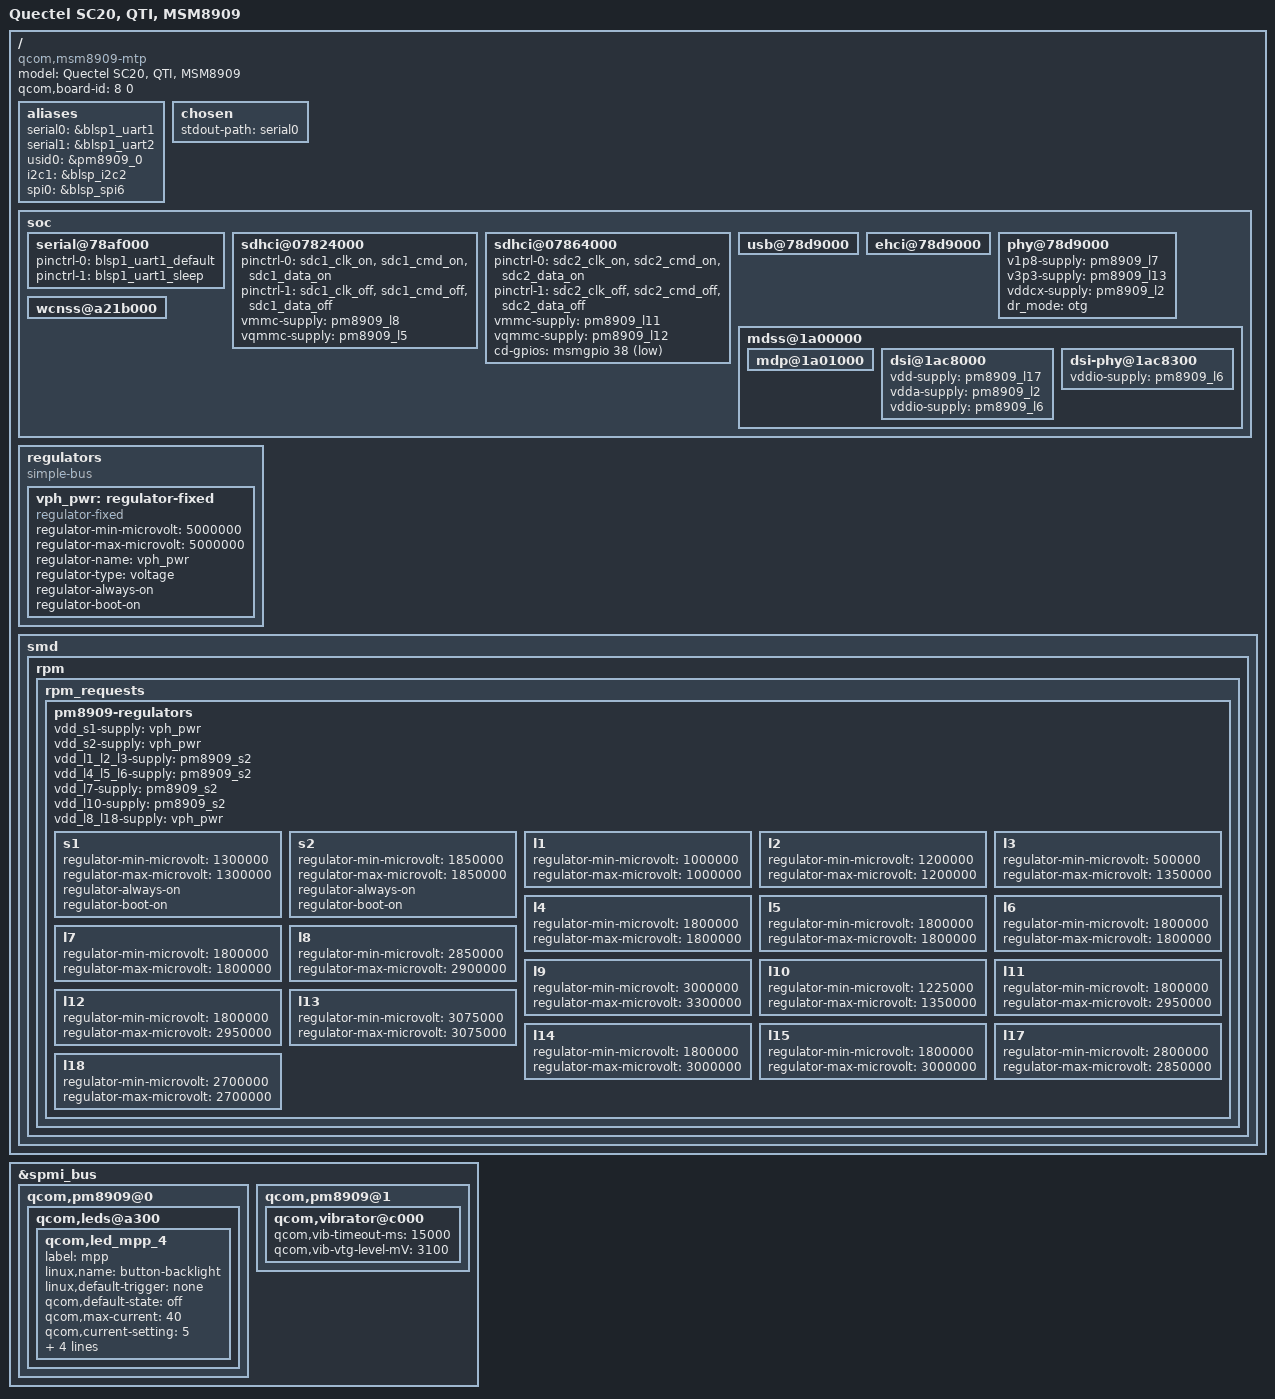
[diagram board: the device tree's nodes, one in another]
// SPDX-License-Identifier: GPL-2.0
/* Copyright (c) 2016, The Linux Foundation. All rights reserved. */
/* Copyright (c) 2019, Ramon Rebersak <ramonr@aplit-soft.com> */
/dts-v1/;

#include "qcom-msm8909.dtsi"
#include "qcom-pm8909.dtsi"
#include <dt-bindings/gpio/gpio.h>
#include <dt-bindings/input/input.h>

/ {
	model = "Quectel SC20, QTI, MSM8909";
	compatible = "qcom,msm8909-mtp", "qcom,msm8909", "qcom,mtp";
	qcom,board-id = <8 0>;

	aliases {
		serial0 = &blsp1_uart1;
		serial1 = &blsp1_uart2;
		usid0 = &pm8909_0;
		i2c1	= &blsp_i2c2;
		spi0	= &blsp_spi6;

	};

	chosen {
		stdout-path = "serial0";
	};

	soc {
		serial@78af000 {
			status = "okay";
			pinctrl-names = "default", "sleep";
			pinctrl-0 = <&blsp1_uart1_default>;
			pinctrl-1 = <&blsp1_uart1_sleep>;
		};
//
//		sdhci@7824000 {
//			vmmc-supply = <&pm8909_l8>;
//			vqmmc-supply = <&pm8909_l5>;
//
//			pinctrl-names = "default", "sleep";
//			pinctrl-0 = <&sdc1_clk_on &sdc1_cmd_on &sdc1_data_on>;
//			pinctrl-1 = <&sdc1_clk_off &sdc1_cmd_off &sdc1_data_off>;
//			status = "okay";
//		};
//
//		sdhci@07864000 {
//			vmmc-supply = <&pm8909_l11>;
//			vqmmc-supply = <&pm8909_l12>;
//
//			pinctrl-names = "default", "sleep";
//			pinctrl-0 = <&sdc2_clk_on &sdc2_cmd_on &sdc2_data_on &sdc2_cd_on>;
//			pinctrl-1 = <&sdc2_clk_off &sdc2_cmd_off &sdc2_data_off &sdc2_cd_off>;
//
//			cd-gpios = <&msmgpio 38 0x1>;
//			status = "okay";
//		};
///
		sdhci@07824000 {
			status = "okay";
			pinctrl-names = "default", "sleep";
			pinctrl-0 = <&sdc1_clk_on &sdc1_cmd_on &sdc1_data_on>;
			pinctrl-1 = <&sdc1_clk_off &sdc1_cmd_off &sdc1_data_off>;
			vmmc-supply = <&pm8909_l8>;
			vqmmc-supply = <&pm8909_l5>;
		};

		sdhci@07864000 {
			status = "okay";
			pinctrl-names = "default", "sleep";
			pinctrl-0 = <&sdc2_clk_on &sdc2_cmd_on &sdc2_data_on>;
			pinctrl-1 = <&sdc2_clk_off &sdc2_cmd_off &sdc2_data_off>;
			vmmc-supply = <&pm8909_l11>;
			vqmmc-supply = <&pm8909_l12>;
			cd-gpios = <&msmgpio 38 0x1>;
		};

		usb@78d9000 {
			status = "okay";
		};

		ehci@78d9000 {
			status = "okay";
		};

		phy@78d9000 {
			v1p8-supply = <&pm8909_l7>;
			v3p3-supply = <&pm8909_l13>;
			vddcx-supply = <&pm8909_l2>;
			dr_mode = "otg";
			status = "okay";
		};

		mdss@1a00000 {
			status = "okay";

			mdp@1a01000 {
				status = "okay";
			};

			dsi@1ac8000 {
				status = "okay";

				vdd-supply = <&pm8909_l17>;
				vdda-supply = <&pm8909_l2>;
				vddio-supply = <&pm8909_l6>;
			};

			dsi-phy@1ac8300 {
				status = "okay";

				vddio-supply = <&pm8909_l6>;
			};
		};

		wcnss@a21b000 {
			status = "okay";
                };
	};

	regulators {
		compatible = "simple-bus";

		vph_pwr: regulator-fixed {
			compatible = "regulator-fixed";
			regulator-min-microvolt = <5000000>;
			regulator-max-microvolt = <5000000>;
			regulator-name = "vph_pwr";
			regulator-type = "voltage";
			regulator-always-on;
			regulator-boot-on;
		};

	};

	smd {
		rpm {
			rpm_requests {
				pm8909-regulators {
					vdd_s1-supply = <&vph_pwr>;
					vdd_s2-supply = <&vph_pwr>;
					vdd_l1_l2_l3-supply = <&pm8909_s2>;
					vdd_l4_l5_l6-supply = <&pm8909_s2>;
					vdd_l7-supply = <&pm8909_s2>;
					vdd_l10-supply = <&pm8909_s2>;
					vdd_l8_l18-supply = <&vph_pwr>;

					s1 {
						regulator-min-microvolt = <1300000>;
						regulator-max-microvolt = <1300000>;
						regulator-always-on;
						regulator-boot-on;
					};

					s2 {
						regulator-min-microvolt = <1850000>;
						regulator-max-microvolt = <1850000>;
						regulator-always-on;
						regulator-boot-on;
					};

					l1 {
						regulator-min-microvolt = <1000000>;
						regulator-max-microvolt = <1000000>;
					};

					l2 {
						regulator-min-microvolt = <1200000>;
						regulator-max-microvolt = <1200000>;
					};

					l3 {
						regulator-min-microvolt = <500000>;
						regulator-max-microvolt = <1350000>;
					};

					l4 {
						regulator-min-microvolt = <1800000>;
						regulator-max-microvolt = <1800000>;
					};

					l5 {
						regulator-min-microvolt = <1800000>;
						regulator-max-microvolt = <1800000>;
						status = "okay";
					};

					l6 {
						regulator-min-microvolt = <1800000>;
						regulator-max-microvolt = <1800000>;
					};

					l7 {
						regulator-min-microvolt = <1800000>;
						regulator-max-microvolt = <1800000>;
					};

					l8 {
						regulator-min-microvolt = <2850000>;
						regulator-max-microvolt = <2900000>;
						status = "okay";
					};

					l9 {
						regulator-min-microvolt = <3000000>;
						regulator-max-microvolt = <3300000>;
					};

					l10 {
						regulator-min-microvolt = <1225000>;
						regulator-max-microvolt = <1350000>;
					};

					l11 {
						regulator-min-microvolt = <1800000>;
						regulator-max-microvolt = <2950000>;
					};

					l12 {
						regulator-min-microvolt = <1800000>;
						regulator-max-microvolt = <2950000>;
					};

					l13 {
						regulator-min-microvolt = <3075000>;
						regulator-max-microvolt = <3075000>;
					};

					l14 {
						regulator-min-microvolt = <1800000>;
						regulator-max-microvolt = <3000000>;
					};

					l15 {
						regulator-min-microvolt = <1800000>;
						regulator-max-microvolt = <3000000>;
					};

					l17 {
						regulator-min-microvolt = <2800000>;
						regulator-max-microvolt = <2850000>;
					};

					l18 {
						regulator-min-microvolt = <2700000>;
						regulator-max-microvolt = <2700000>;
					};
				};
			};
		};
	};
};

&spmi_bus {
	qcom,pm8909@0 {
		qcom,leds@a300 {
			status = "okay";
			qcom,led_mpp_4 {
				label = "mpp";
				linux,name = "button-backlight";
				linux,default-trigger = "none";
				qcom,default-state = "off";
				qcom,max-current = <40>;
				qcom,current-setting = <5>;
				qcom,id = <6>;
				qcom,mode = "manual";
				qcom,source-sel = <1>;
				qcom,mode-ctrl = <0x60>;
			};
		};
	};

	qcom,pm8909@1 {
		qcom,vibrator@c000 {
			status = "okay";
			qcom,vib-timeout-ms = <15000>;
			qcom,vib-vtg-level-mV = <3100>;
		};
	};
};
